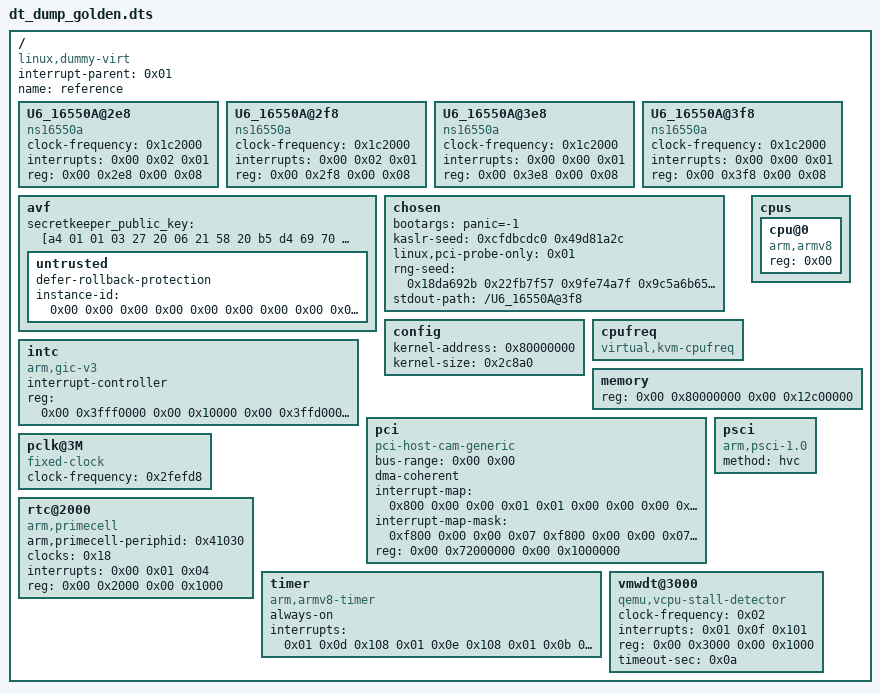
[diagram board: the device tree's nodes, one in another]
/dts-v1/;

/ {
	#address-cells = <0x02>;
	#size-cells = <0x02>;
	compatible = "linux,dummy-virt";
	interrupt-parent = <0x01>;
	name = "reference";

	U6_16550A@2e8 {
		clock-frequency = <0x1c2000>;
		compatible = "ns16550a";
		interrupts = <0x00 0x02 0x01>;
		reg = <0x00 0x2e8 0x00 0x08>;
	};

	U6_16550A@2f8 {
		clock-frequency = <0x1c2000>;
		compatible = "ns16550a";
		interrupts = <0x00 0x02 0x01>;
		reg = <0x00 0x2f8 0x00 0x08>;
	};

	U6_16550A@3e8 {
		clock-frequency = <0x1c2000>;
		compatible = "ns16550a";
		interrupts = <0x00 0x00 0x01>;
		reg = <0x00 0x3e8 0x00 0x08>;
	};

	U6_16550A@3f8 {
		clock-frequency = <0x1c2000>;
		compatible = "ns16550a";
		interrupts = <0x00 0x00 0x01>;
		reg = <0x00 0x3f8 0x00 0x08>;
	};

	__symbols__ {
		intc = "/intc";
	};

	avf {
		secretkeeper_public_key = [a4 01 01 03 27 20 06 21 58 20 b5 d4 69 70 1d a4 d9 06 a3 70 4e d4 3e 2f 62 f1 2f 80 ba 27 ef 19 b6 21 c2 7a 98 4a 04 a5 f2 b0];

		untrusted {
			defer-rollback-protection;
			instance-id = <0x00 0x00 0x00 0x00 0x00 0x00 0x00 0x00 0x00 0x00 0x00 0x00 0x00 0x00 0x00 0x00>;
		};
	};

	chosen {
		bootargs = "panic=-1";
		kaslr-seed = <0xcfdbcdc0 0x49d81a2c>;
		linux,pci-probe-only = <0x01>;
		rng-seed = <0x18da692b 0x22fb7f57 0x9fe74a7f 0x9c5a6b65 0xe28535a8 0x98ffd621 0x2b89e928 0xe8fdd175 0xb5bd347e 0xfc1b22cc 0x8e9437eb 0x4e368382 0x3395c024 0x744aaed6 0x65cdc8c8 0x128b610a 0x773b0e30 0xac38711b 0x76b0bdf9 0xaa4c7e26 0x654a6576 0x1ffa3603 0x383ecfcf 0x1146b09b 0x2e67701b 0x4e18c937 0xc873ce8 0x523b08d 0x35c8079d 0x915ed985 0x5fdfa7b9 0xeeb7e501 0xcb910bb6 0x63af1b6f 0x4e2799c9 0xf6ac1b8c 0xb48ff156 0x92e14355 0xd3192934 0xc9474cdf 0x6db7484d 0x808f2a48 0x11ef7063 0xa00cf2b 0xa95e5bdc 0xd1fa7dbd 0x24485379 0xf3cb8899 0x97a9f491 0x45528aaa 0x8134bba9 0xa859a650 0x2a51ddec 0x7ff1ae 0x9b9fdcc3 0xeeee47d6 0x2e965119 0xe0c7069e 0xaa8b0b3f 0x1d2fe873 0x510be6b3 0x91e7d34e 0x6926bc36 0x7b743c95>;
		stdout-path = "/U6_16550A@3f8";
	};

	config {
		kernel-address = <0x80000000>;
		kernel-size = <0x2c8a0>;
	};

	cpufreq {
		compatible = "virtual,kvm-cpufreq";
	};

	cpus {
		#address-cells = <0x01>;
		#size-cells = <0x00>;

		cpu@0 {
			compatible = "arm,armv8";
			device_type = "cpu";
			phandle = <0x100>;
			reg = <0x00>;
		};
	};

	intc {
		#address-cells = <0x02>;
		#interrupt-cells = <0x03>;
		#size-cells = <0x02>;
		compatible = "arm,gic-v3";
		interrupt-controller;
		phandle = <0x01>;
		reg = <0x00 0x3fff0000 0x00 0x10000 0x00 0x3ffd0000 0x00 0x20000>;
	};

	memory {
		device_type = "memory";
		reg = <0x00 0x80000000 0x00 0x12c00000>;
	};

	pci {
		#address-cells = <0x03>;
		#interrupt-cells = <0x01>;
		#size-cells = <0x02>;
		bus-range = <0x00 0x00>;
		compatible = "pci-host-cam-generic";
		device_type = "pci";
		dma-coherent;
		interrupt-map = <0x800 0x00 0x00 0x01 0x01 0x00 0x00 0x00 0x04 0x04 0x1000 0x00 0x00 0x01 0x01 0x00 0x00 0x00 0x05 0x04 0x1800 0x00 0x00 0x01 0x01 0x00 0x00 0x00 0x06 0x04 0x2000 0x00 0x00 0x01 0x01 0x00 0x00 0x00 0x07 0x04 0x2800 0x00 0x00 0x01 0x01 0x00 0x00 0x00 0x08 0x04 0x3000 0x00 0x00 0x01 0x01 0x00 0x00 0x00 0x09 0x04 0x3800 0x00 0x00 0x01 0x01 0x00 0x00 0x00 0x0a 0x04 0x4000 0x00 0x00 0x01 0x01 0x00 0x00 0x00 0x0b 0x04>;
		interrupt-map-mask = <0xf800 0x00 0x00 0x07 0xf800 0x00 0x00 0x07 0xf800 0x00 0x00 0x07 0xf800 0x00 0x00 0x07 0xf800 0x00 0x00 0x07 0xf800 0x00 0x00 0x07 0xf800 0x00 0x00 0x07 0xf800 0x00 0x00 0x07>;
		ranges = <0x3000000 0x00 0x70000000 0x00 0x70000000 0x00 0x2000000 0x43000000 0x00 0x93400000 0x00 0x93400000 0xff 0x6cc00000>;
		reg = <0x00 0x72000000 0x00 0x1000000>;
	};

	pclk@3M {
		#clock-cells = <0x00>;
		clock-frequency = <0x2fefd8>;
		compatible = "fixed-clock";
		phandle = <0x18>;
	};

	psci {
		compatible = "arm,psci-1.0\0arm,psci-0.2";
		method = "hvc";
	};

	rtc@2000 {
		arm,primecell-periphid = <0x41030>;
		clock-names = "apb_pclk";
		clocks = <0x18>;
		compatible = "arm,primecell";

		interrupts = <0x00 0x01 0x04>;
		reg = <0x00 0x2000 0x00 0x1000>;
	};

	timer {
		always-on;
		compatible = "arm,armv8-timer";
		interrupts = <0x01 0x0d 0x108 0x01 0x0e 0x108 0x01 0x0b 0x108 0x01 0x0a 0x108>;
	};

	vmwdt@3000 {
		clock-frequency = <0x02>;
		compatible = "qemu,vcpu-stall-detector";
		interrupts = <0x01 0x0f 0x101>;
		reg = <0x00 0x3000 0x00 0x1000>;
		timeout-sec = <0x0a>;
	};
};
